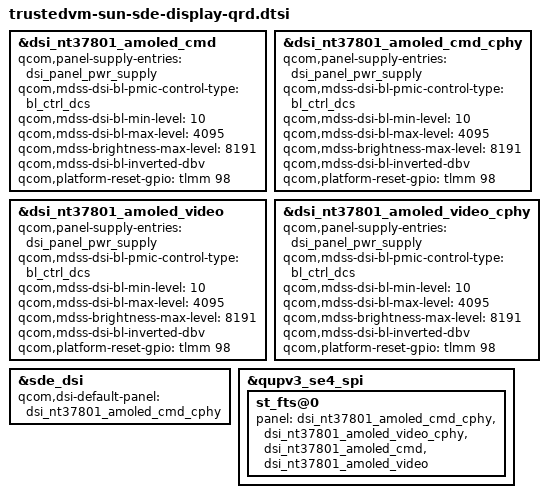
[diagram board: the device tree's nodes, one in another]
// SPDX-License-Identifier: BSD-3-Clause
/*
 * Copyright (c) 2023-2024 Qualcomm Innovation Center, Inc. All rights reserved.
 */

#include "trustedvm-sun-sde-display.dtsi"

&dsi_nt37801_amoled_cmd {
	qcom,panel-supply-entries = <&dsi_panel_pwr_supply>;
	qcom,mdss-dsi-bl-pmic-control-type = "bl_ctrl_dcs";
	qcom,mdss-dsi-bl-min-level = <10>;
	qcom,mdss-dsi-bl-max-level = <4095>;
	qcom,mdss-brightness-max-level = <8191>;
	qcom,mdss-dsi-bl-inverted-dbv;
	qcom,platform-reset-gpio = <&tlmm 98 0>;
};

&dsi_nt37801_amoled_cmd_cphy {
	qcom,panel-supply-entries = <&dsi_panel_pwr_supply>;
	qcom,mdss-dsi-bl-pmic-control-type = "bl_ctrl_dcs";
	qcom,mdss-dsi-bl-min-level = <10>;
	qcom,mdss-dsi-bl-max-level = <4095>;
	qcom,mdss-brightness-max-level = <8191>;
	qcom,mdss-dsi-bl-inverted-dbv;
	qcom,platform-reset-gpio = <&tlmm 98 0>;
};

&dsi_nt37801_amoled_video {
	qcom,panel-supply-entries = <&dsi_panel_pwr_supply>;
	qcom,mdss-dsi-bl-pmic-control-type = "bl_ctrl_dcs";
	qcom,mdss-dsi-bl-min-level = <10>;
	qcom,mdss-dsi-bl-max-level = <4095>;
	qcom,mdss-brightness-max-level = <8191>;
	qcom,mdss-dsi-bl-inverted-dbv;
	qcom,platform-reset-gpio = <&tlmm 98 0>;
};

&dsi_nt37801_amoled_video_cphy {
	qcom,panel-supply-entries = <&dsi_panel_pwr_supply>;
	qcom,mdss-dsi-bl-pmic-control-type = "bl_ctrl_dcs";
	qcom,mdss-dsi-bl-min-level = <10>;
	qcom,mdss-dsi-bl-max-level = <4095>;
	qcom,mdss-brightness-max-level = <8191>;
	qcom,mdss-dsi-bl-inverted-dbv;
	qcom,platform-reset-gpio = <&tlmm 98 0>;
};

&sde_dsi {
	qcom,dsi-default-panel = <&dsi_nt37801_amoled_cmd_cphy>;
};

&qupv3_se4_spi {
	st_fts@0 {
		panel = <&dsi_nt37801_amoled_cmd_cphy
			&dsi_nt37801_amoled_video_cphy
			&dsi_nt37801_amoled_cmd
			&dsi_nt37801_amoled_video>;
	};
};
